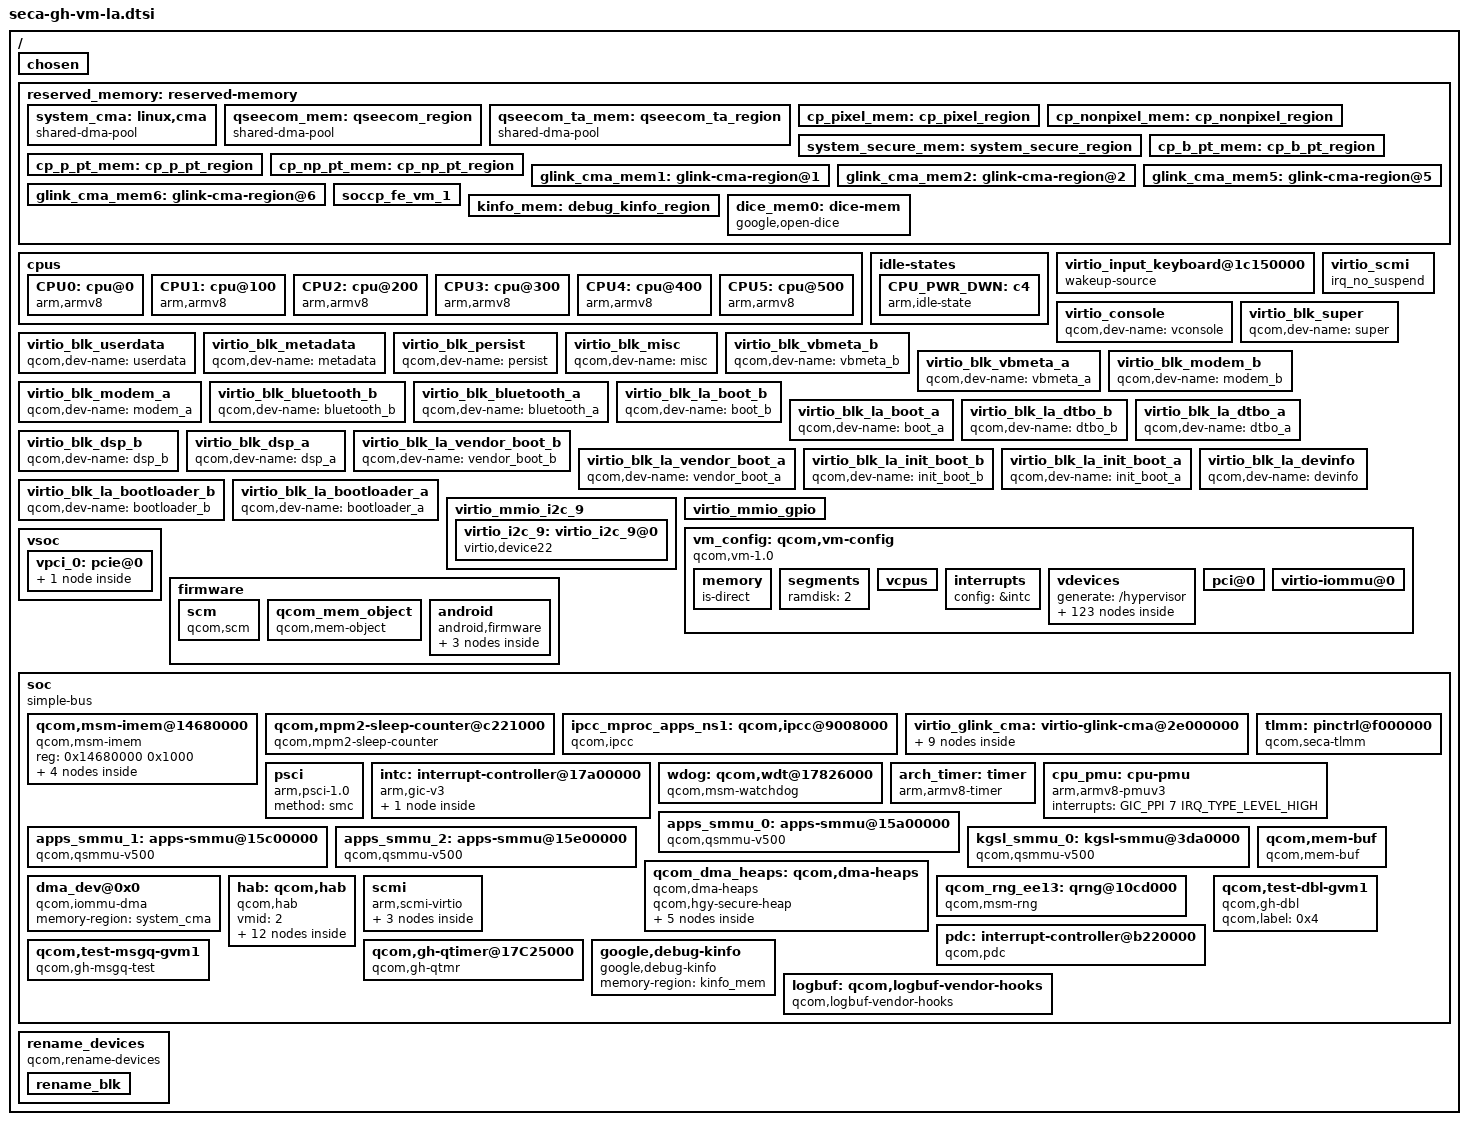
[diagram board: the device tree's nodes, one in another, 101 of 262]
// SPDX-License-Identifier: BSD-3-Clause
/*
 * Copyright (c) Qualcomm Technologies, Inc. and/or its subsidiaries.
 */

#include <dt-bindings/interrupt-controller/arm-gic.h>
#include <dt-bindings/arm/msm/qcom_dma_heap_dt_constants.h>
#include <dt-bindings/mailbox/qcom-ipcc.h>
#include <dt-bindings/soc/qcom,ipcc.h>
#include <dt-bindings/mailbox/qcom-ipcc-sa8797p.h>

/ {
	#address-cells = <0x2>;
	#size-cells = <0x2>;
	qcom,msm-name = "SA_GUNYAH_VM";
	interrupt-parent = <&intc>;

	chosen {
		bootargs = "console=hvc0 root=/dev/ram rw rootwait nokaslr log_buf_len=1M ufshcd-core.use_mcq_mode=n kpti=0 loglevel=8 printk.devkmsg=on maxcpus=6 driver_async_probe=arm-scmi fw_devlink.strict=1 iommu.strict=0";
		bootconfig = "androidboot.fstab_suffix=hgy.seca.qcom";
	};

	reserved_memory: reserved-memory {
		#address-cells = <2>;
		#size-cells = <2>;
		ranges;

		system_cma: linux,cma {
			compatible = "shared-dma-pool";
			alloc-ranges = <0x0 0x0 0x0 0xffffffff>;
			reusable;
			alignment = <0x0 0x400000>;
			size = <0x0 0x2000000>;
			linux,cma-default;
		};

		qseecom_mem: qseecom_region {
			compatible = "shared-dma-pool";
			alloc-ranges = <0x0 0x00000000 0x0 0xffffffff>;
			reusable;
			alignment = <0x0 0x400000>;
			size = <0x0 0x1400000>;
		};

		qseecom_ta_mem: qseecom_ta_region {
			compatible = "shared-dma-pool";
			alloc-ranges = <0x0 0x00000000 0x0 0xffffffff>;
			reusable;
			alignment = <0x0 0x400000>;
			size = <0x0 0x1000000>;
		};

		cp_pixel_mem: cp_pixel_region {
			no-map;
			qcom,target-vmid = <0xa>;
			qcom,label = <0xc0a>;
			qcom,unmapped;
		};

		cp_nonpixel_mem: cp_nonpixel_region {
			no-map;
			qcom,target-vmid = <0xb>;
			qcom,label = <0xc0b>;
			qcom,unmapped;
		};

		system_secure_mem: system_secure_region {
			no-map;
			qcom,label = <0xc09>;
			qcom,target-vmid = <0x9>;
			qcom,unmapped;
		};

		cp_b_pt_mem: cp_b_pt_region {
			qcom,label = <0x9A>;
			qcom,secure-pt-reserved;
		};

		cp_p_pt_mem: cp_p_pt_region {
			qcom,label = <0x9B>;
			qcom,secure-pt-reserved;
		};

		cp_np_pt_mem: cp_np_pt_region {
			qcom,label = <0x9C>;
			qcom,secure-pt-reserved;
		};

		glink_cma_mem1: glink-cma-region@1 {
			no-map;
			qcom,label = <0x60>;
		};

		glink_cma_mem2: glink-cma-region@2 {
			no-map;
			qcom,label = <0x61>;
		};

		glink_cma_mem5: glink-cma-region@5 {
			no-map;
			qcom,label = <0x64>;
		};

		glink_cma_mem6: glink-cma-region@6 {
			no-map;
			qcom,label = <0x65>;
		};

		soccp_fe_vm_1: soccp_fe_vm_1 {
			no-map;
			qcom,label = <0x80>;
		};

		kinfo_mem: debug_kinfo_region {
			alloc-ranges = <0x0 0x0 0xffffffff 0xffffffff>;
			size = <0x0 0x1000>;
			no-map;
		};

		dice_mem0: dice-mem {
			compatible = "google,open-dice";
			no-map;
			qcom,label = <0x67>;
		};

	};

	cpus {
		#address-cells = <0x2>;
		#size-cells = <0x0>;

		CPU0: cpu@0 {
			compatible = "arm,armv8";
			reg = <0x0 0x0>;
			device_type = "cpu";
			enable-method = "psci";
			cpu-idle-states = <&CPU_PWR_DWN>;
		};

		CPU1: cpu@100 {
			compatible = "arm,armv8";
			reg = <0x0 0x100>;
			device_type = "cpu";
			enable-method = "psci";
			cpu-idle-states = <&CPU_PWR_DWN>;
		};

		CPU2: cpu@200 {
			compatible = "arm,armv8";
			reg = <0x0 0x200>;
			device_type = "cpu";
			enable-method = "psci";
			cpu-idle-states = <&CPU_PWR_DWN>;
		};

		CPU3: cpu@300 {
			compatible = "arm,armv8";
			reg = <0x0 0x300>;
			device_type = "cpu";
			enable-method = "psci";
			cpu-idle-states = <&CPU_PWR_DWN>;
		};

		CPU4: cpu@400 {
			compatible = "arm,armv8";
			reg = <0x0 0x400>;
			device_type = "cpu";
			enable-method = "psci";
			cpu-idle-states = <&CPU_PWR_DWN>;
		};

		CPU5: cpu@500 {
			compatible = "arm,armv8";
			reg = <0x0 0x500>;
			device_type = "cpu";
			enable-method = "psci";
			cpu-idle-states = <&CPU_PWR_DWN>;
		};
	};

	idle-states {
		CPU_PWR_DWN: c4 { /* C4 */
			compatible = "arm,idle-state";
			idle-state-name = "ret";
			entry-latency-us = <93>;
			exit-latency-us = <129>;
			min-residency-us = <560>;
			arm,psci-suspend-param = <0x00000003>;
			local-timer-stop;
		};
	};

	virtio_input_keyboard@1c150000 {
		wakeup-source;
	};

	virtio_console {
		qcom,dev-name = "vconsole";
	};

	virtio_scmi {
		irq_no_suspend;
	};

	virtio_blk_super {
		qcom,dev-name = "super";
	};

	virtio_blk_userdata {
		qcom,dev-name = "userdata";
	};

	virtio_blk_metadata {
		qcom,dev-name = "metadata";
	};

	virtio_blk_persist {
		qcom,dev-name = "persist";
	};

	virtio_blk_misc {
		qcom,dev-name = "misc";
	};

	virtio_blk_vbmeta_b {
		qcom,dev-name = "vbmeta_b";
	};

	virtio_blk_vbmeta_a {
		qcom,dev-name = "vbmeta_a";
	};

	virtio_blk_modem_b {
		qcom,dev-name = "modem_b";
	};

	virtio_blk_modem_a {
		qcom,dev-name = "modem_a";
	};

	virtio_blk_bluetooth_b {
		qcom,dev-name = "bluetooth_b";
	};

	virtio_blk_bluetooth_a {
		qcom,dev-name = "bluetooth_a";
	};

	virtio_blk_la_boot_b {
		qcom,dev-name = "boot_b";
	};

	virtio_blk_la_boot_a {
		qcom,dev-name = "boot_a";
	};

	virtio_blk_la_dtbo_b {
		qcom,dev-name = "dtbo_b";
	};

	virtio_blk_la_dtbo_a {
		qcom,dev-name = "dtbo_a";
	};

	virtio_blk_dsp_b {
		qcom,dev-name = "dsp_b";
	};

	virtio_blk_dsp_a {
		qcom,dev-name = "dsp_a";
	};

	virtio_blk_la_vendor_boot_b {
		qcom,dev-name = "vendor_boot_b";
	};

	virtio_blk_la_vendor_boot_a {
		qcom,dev-name = "vendor_boot_a";
	};

	virtio_blk_la_init_boot_b {
		qcom,dev-name = "init_boot_b";
	};

	virtio_blk_la_init_boot_a {
		qcom,dev-name = "init_boot_a";
	};

	virtio_blk_la_devinfo {
		qcom,dev-name = "devinfo";
	};

	virtio_blk_la_bootloader_b {
		qcom,dev-name = "bootloader_b";
	};

	virtio_blk_la_bootloader_a {
		qcom,dev-name = "bootloader_a";
	};

	virtio_mmio_i2c_9 {
		virtio_i2c_9: virtio_i2c_9@0 {
			compatible = "virtio,device22";
		};
	};

	virtio_mmio_gpio {
	};

	vm_config: qcom,vm-config {
		compatible = "qcom,vm-1.0";
		vm-type = "aarch64-guest";
		boot-config = "fdt,unified";
		os-type = "linux";
		kernel-entry-segment = "kernel";
		kernel-entry-offset = <0x0 0x0>;
		vendor = "QTI";
		image-name = "qcom,autogvm";
		qcom,pasid = <0x0 0x2c>;
		qcom,qtee-config-info = "p=3,16,57,77,78,7A,7C,8F,97,159,199,47E,7F1,10C;ta=keymaster64,widevine,pr_3_0,she_gvm,wvqcomkeyprov,drmsampleapp,smpcpyap64,featenabler,auto_test_a,auto_test_b,auto_test_c,auto_test_d,auto_test_e,auto_test_f,auto_test_g,auto_test_h,auto_test_i,auto_test_j,auto_test_k,auto_test_l,auto_test_m,auto_test_n,auto_test_o,auto_test_p,auto_test_320,auto_test_321,auto_test_322,auto_test_323,auto_test_324,apttestapp,apttestapp64,aptcryptotestapp,aptcryptotestapp64,smplserv,tzecotestapp,tzecotestappcbo1,smci_auto_test_1,smci_auto_test_2,smci_auto_test_3,smci_auto_test_4,smci_auto_test_5,smci_auto_test_6,smci_auto_test_7,smci_auto_test_8,smci_auto_test_9,smci_auto_test_10,smci_auto_test_11,smci_auto_test_12,smci_auto_test_13,smci_auto_test_14,smci_auto_test_15,smci_auto_test_16,smci_auto_test_init_crash,smci_auto_test_restartable,smci_auto_test_shutdown_crash,fsp_test_1,fsp_test_2,fsp_test_3,bintestapp64,tzecotestapp1,crypto_testapp,sst_testapp,autosst_testapp,auto_test_unpermitted,FD02C9DA-306C-48C7-A49C-BBD827AE86EF,5AF8C3E6-D9DF-446E-4FF2-D4D58E8CA49B,19CE19B9-FD73-4262-8553-E5CAC40C895A,C02CAC07-2639-4EF0-BC12-C4AF1FB3E276,15C6B6E4-D083-48E4-8744-4D90A8FF1EF2,CAD10542-34E4-452D-6156-E979AA6E61BC,23914957-C174-4EA6-54D1-DA820F77B4B0,5AF8C3E6-D9DF-446E-4FF2-C3C47D7B938A,CAD10542-34E4-452D-6156-E979AA6E6132,5AF8C3E6-D9DF-446E-4FF2-B2B36C6A8279,5AF8C3E6-D9DF-446E-4FF2-D4D58E8CA49B,19CE19B9-FD73-4262-8553-E5CAC40C895A,C02CAC07-2639-4EF0-BC12-C4AF1FB3E276,15C6B6E4-D083-48E4-8744-4D90A8FF1EF2,CAD10542-34E4-452D-6156-E979AA6E61BC,23914957-C174-4EA6-54D1-DA820F77B4B0,5AF8C3E6-D9DF-446E-4FF2-C3C47D7B938A,CAD10542-34E4-452D-6156-E979AA6E6132,5AF8C3E6-D9DF-446E-4FF2-B2B36C6A8279,9824F733-FAC7-502A-81A0-84F6EE3DDACE,20F800CD-0E9B-55CF-A363-1498C26C7100,F577386D-AE4A-5728-921F-F97407BB30A0,3F3E0440-3CD7-5A81-A5DF-6AEB9A0A096C,2DB53398-CA4E-5342-BDED-4544A9039DEA,4C179CF2-22E0-5860-982F-5BBE195F9B0A,CE79BE1D-B0A5-5E69-87C6-6524649F1BEC,F54046B4-11FA-5F76-B4CC-39F58AF4011F,D1DB4C3F-B1E5-5A7F-817E-B49AF2632D1A,2F9D7B61-C79B-5D0B-8FA5-ECCFAE233B7C,220249E5-787C-5F61-B7E6-F69E589F37D6,D4ADCDC0-FF3F-52FA-9267-23971A192A73,0E0F184C-A5F3-543F-9CBF-5104168FE101,1B196214-0457-5774-B768-E8B6F139BECC,AE80F099-54A0-532B-A7BF-58DDB08F2407,E0C6693B-0945-5E72-9385-D71353B81721,10D761D9-037A-51E3-9955-028AF5A77FBA,D9BCD049-9321-52CC-B310-A62789FF3833,3BAA90A5-E4BA-52E9-9A63-EF71FF188B81,71BACACB-52EB-53A5-AA61-510923212679,8A0B3DF4-4947-49E4-85A7-67D7D73B5314,DC0ED4E6-819A-4560-BF13-B4948A7B4379,FF722055-FDC3-4C17-B53D-669E19A358F8,BEE83CCC-0DCC-420F-BAF6-F3F8B48DB22D,534D4152-542D-4353-4C54-2D54412D4552,534D4152-5443-534C-5445-5252544F4F53,534D4152-542D-4353-4C54-2D54412D5355,534D4152-5443-534C-544F-53345041524D,534D4152-542D-4353-4C54-2D54412D5354,534D4152-5443-534C-5443-4C4950415241,534D4152-5443-534C-5443-4C49504F5053,534D4152-542D-4353-4C54-2D54412D3031,534D4152-5443-534C-5441-544346494341,534d4152-5443-534c-5454-434649434132,534D4152-5443-534C-4D4C-54494E535443,534D4152-5443-534C-5347-4C494E535443,534D4152-5443-534C-434C-4F50414E4943,534D4152-5443-4C53-4152-4954484D4554,534D4152-5443-534C-5443-525950544F31,534D4152-5443-534C-5444-415441535431,534D4152-5443-534C-5F54-494D45415049,5AB106AE-7F60-11EA-BC55-0242AC130003,4E3F7FF3-7EDE-45FD-9BAA-7863611E0897,smplap64,ukpapp,unified_key_prov,ukpclnt,sbservice;";
		qcom,secdomain-ids = <52 9 10>;
		qcom,primary-vm-index = <0>;
		vm-attrs = "guest-ram-dump" ,"vpm-virq", "allow-unprotected";
		qcom,peripheral-vmids = <0x9 0xa 0xb>;

		virtio-iommu-stream-id-ranges-temp = <0x20000 0x10000 0x30000 0x10000>;
		vits-device-id-ranges-temp = <0xa0000 0x1 0xa0100 0x1 0xb0000 0x1 0xb0100 0x1>;

		memory {
			#address-cells = <0x2>;
			#size-cells = <0x0>;

			/* The IPA of the Guest regions is placed as IPA=PA */
			is-direct;
		};

		segments {
			ramdisk = <2>;
		};

		vcpus {
			config = "/cpus";
			affinity = "pinned";
			sched-priority = <0>;       /* relative to PVM */
			sched-timeslice = <5000>;   /* in ms */
		};

		interrupts {
			config = &intc;
		};

		vdevices {
			generate = "/hypervisor";

			minidump {
				vdevice-type = "minidump";
				push-compatible = "qcom,minidump_rm";
				minidump_allowed;
			};

			rm-rpc {
				vdevice-type = "rm-rpc";
				generate = "/hypervisor/qcom,resource-mgr";
				console-dev;
				message-size = <0x000000f0>;
				queue-depth = <0x00000008>;
				qcom,label = <0x1>;
			};

			virtio-mmio@0 {
				vdevice-type = "virtio-mmio";
				generate = "/virtio-mmio";
				peer-default;
				vqs-num = <0x1>;
				push-compatible = "virtio,mmio";
				sync-reset;
				dma-coherent;
				dma_base = <0x0 0x0>;
				memory {
					qcom,label = <0x20>;
					#address-cells = <0x2>;
					allocate-base;
				};
			};

			virtio-mmio@1 {
				vdevice-type = "virtio-mmio";
				patch = "/virtio_blk_la_devinfo";
				peer-default;
				vqs-num = <0x1>;
				push-compatible = "virtio,mmio";
				sync-reset;
				dma-coherent;
				dma_base = <0x0 0x4000>;
				memory {
					qcom,label = <0x21>;
					#address-cells = <0x2>;
					allocate-base;
				};
			};

			virtio-mmio@2 {
				vdevice-type = "virtio-mmio";
				patch = "/virtio_blk_la_init_boot_a";
				peer-default;
				vqs-num = <0x1>;
				push-compatible = "virtio,mmio";
				sync-reset;
				dma-coherent;
				dma_base = <0x0 0x8000>;
				memory {
					qcom,label = <0x22>;
					#address-cells = <0x2>;
					allocate-base;
				};
			};

			virtio-mmio@3 {
				vdevice-type = "virtio-mmio";
				patch = "/virtio_blk_la_init_boot_b";
				peer-default;
				vqs-num = <0x1>;
				push-compatible = "virtio,mmio";
				sync-reset;
				dma-coherent;
				dma_base = <0x0 0xC000>;
				memory {
					qcom,label = <0x23>;
					#address-cells = <0x2>;
					allocate-base;
				};
			};

			virtio-mmio@4 {
				vdevice-type = "virtio-mmio";
				patch = "/virtio_blk_la_vendor_boot_a";
				peer-default;
				vqs-num = <0x1>;
				push-compatible = "virtio,mmio";
				sync-reset;
				dma-coherent;
				dma_base = <0x0 0x10000>;
				memory {
					qcom,label = <0x24>;
					#address-cells = <0x2>;
					allocate-base;
				};
			};

			virtio-mmio@5 {
				vdevice-type = "virtio-mmio";
				patch = "/virtio_blk_la_vendor_boot_b";
				peer-default;
				vqs-num = <0x1>;
				push-compatible = "virtio,mmio";
				sync-reset;
				dma-coherent;
				dma_base = <0x0 0x14000>;
				memory {
					qcom,label = <0x25>;
					#address-cells = <0x2>;
					allocate-base;
				};
			};

			virtio-mmio@6 {
				vdevice-type = "virtio-mmio";
				patch = "/virtio_blk_dsp_a";
				peer-default;
				vqs-num = <0x1>;
				push-compatible = "virtio,mmio";
				sync-reset;
				dma-coherent;
				dma_base = <0x0 0x18000>;
				memory {
					qcom,label = <0x26>;
					#address-cells = <0x2>;
					allocate-base;
				};
			};

			virtio-mmio@7 {
				vdevice-type = "virtio-mmio";
				patch = "/virtio_blk_dsp_b";
				peer-default;
				vqs-num = <0x1>;
				push-compatible = "virtio,mmio";
				sync-reset;
				dma-coherent;
				dma_base = <0x0 0x1C000>;
				memory {
					qcom,label = <0x27>;
					#address-cells = <0x2>;
					allocate-base;
				};
			};

			virtio-mmio@8 {
				vdevice-type = "virtio-mmio";
				patch = "/virtio_blk_la_dtbo_a";
				peer-default;
				vqs-num = <0x1>;
				push-compatible = "virtio,mmio";
				sync-reset;
				dma-coherent;
				dma_base = <0x0 0x20000>;
				memory {
					qcom,label = <0x28>;
					#address-cells = <0x2>;
					allocate-base;
				};
			};

			virtio-mmio@9 {
				vdevice-type = "virtio-mmio";
				patch = "/virtio_blk_la_dtbo_b";
				peer-default;
				vqs-num = <0x1>;
				push-compatible = "virtio,mmio";
				sync-reset;
				dma-coherent;
				dma_base = <0x0 0x24000>;
				memory {
					qcom,label = <0x29>;
					#address-cells = <0x2>;
					allocate-base;
				};
			};

			virtio-mmio@10 {
				vdevice-type = "virtio-mmio";
				patch = "/virtio_blk_la_boot_a";
				peer-default;
				vqs-num = <0x1>;
				push-compatible = "virtio,mmio";
				sync-reset;
				dma-coherent;
				dma_base = <0x0 0x28000>;
				memory {
					qcom,label = <0x2A>;
					#address-cells = <0x2>;
					allocate-base;
				};
			};

			virtio-mmio@11 {
				vdevice-type = "virtio-mmio";
				patch = "/virtio_blk_la_boot_b";
				peer-default;
				vqs-num = <0x1>;
				push-compatible = "virtio,mmio";
				sync-reset;
				dma-coherent;
				dma_base = <0x0 0x2C000>;
				memory {
					qcom,label = <0x2B>;
					#address-cells = <0x2>;
					allocate-base;
				};
			};

			virtio-mmio@12 {
				vdevice-type = "virtio-mmio";
				patch = "/virtio_blk_bluetooth_a";
				peer-default;
				vqs-num = <0x1>;
				push-compatible = "virtio,mmio";
				sync-reset;
				dma-coherent;
				dma_base = <0x0 0x30000>;
				memory {
					qcom,label = <0x2C>;
					#address-cells = <0x2>;
					allocate-base;
				};
			};

			virtio-mmio@13 {
				vdevice-type = "virtio-mmio";
				patch = "/virtio_blk_bluetooth_b";
				peer-default;
				vqs-num = <0x1>;
				push-compatible = "virtio,mmio";
				sync-reset;
				dma-coherent;
				dma_base = <0x0 0x34000>;
				memory {
					qcom,label = <0x2D>;
					#address-cells = <0x2>;
					allocate-base;
				};
			};

			virtio-mmio@14 {
				vdevice-type = "virtio-mmio";
				patch = "/virtio_blk_modem_a";
				peer-default;
				vqs-num = <0x1>;
				push-compatible = "virtio,mmio";
				sync-reset;
				dma-coherent;
				dma_base = <0x0 0x38000>;
				memory {
					qcom,label = <0x2E>;
					#address-cells = <0x2>;
					allocate-base;
				};
			};

			virtio-mmio@15 {
				vdevice-type = "virtio-mmio";
				patch = "/virtio_blk_modem_b";
				peer-default;
				vqs-num = <0x1>;
				push-compatible = "virtio,mmio";
				sync-reset;
				dma-coherent;
				dma_base = <0x0 0x3C000>;
				memory {
					qcom,label = <0x2F>;
					#address-cells = <0x2>;
					allocate-base;
				};
			};

			virtio-mmio@16 {
				vdevice-type = "virtio-mmio";
				patch = "/virtio_blk_vbmeta_a";
				peer-default;
				vqs-num = <0x1>;
				push-compatible = "virtio,mmio";
				sync-reset;
				dma-coherent;
				dma_base = <0x0 0x40000>;
				memory {
					qcom,label = <0x30>;
					#address-cells = <0x2>;
					allocate-base;
				};
			};

			virtio-mmio@17 {
				vdevice-type = "virtio-mmio";
				patch = "/virtio_blk_vbmeta_b";
				peer-default;
				vqs-num = <0x1>;
				push-compatible = "virtio,mmio";
				sync-reset;
				dma-coherent;
				dma_base = <0x0 0x44000>;
				memory {
					qcom,label = <0x31>;
					#address-cells = <0x2>;
					allocate-base;
				};
			};

			virtio-mmio@18 {
				vdevice-type = "virtio-mmio";
				patch = "/virtio_blk_misc";
				peer-default;
				vqs-num = <0x1>;
				push-compatible = "virtio,mmio";
				sync-reset;
				dma-coherent;
				dma_base = <0x0 0x48000>;
				memory {
					qcom,label = <0x32>;
					#address-cells = <0x2>;
					allocate-base;
				};
			};

			virtio-mmio@19 {
				vdevice-type = "virtio-mmio";
				patch = "/virtio_blk_persist";
				peer-default;
				vqs-num = <0x1>;
				push-compatible = "virtio,mmio";
				sync-reset;
				dma-coherent;
				dma_base = <0x0 0x4C000>;
				memory {
					qcom,label = <0x33>;
					#address-cells = <0x2>;
					allocate-base;
				};
			};

			virtio-mmio@20 {
				vdevice-type = "virtio-mmio";
				patch = "/virtio_blk_metadata";
				peer-default;
				vqs-num = <0x1>;
				push-compatible = "virtio,mmio";
				sync-reset;
				dma-coherent;
				dma_base = <0x0 0x50000>;
				memory {
					qcom,label = <0x34>;
					#address-cells = <0x2>;
					allocate-base;
				};
			};

			virtio-mmio@21 {
				vdevice-type = "virtio-mmio";
				patch = "/virtio_blk_userdata";
				peer-default;
				vqs-num = <0x1>;
				push-compatible = "virtio,mmio";
				sync-reset;
				dma-coherent;
				dma_base = <0x0 0x54000>;
				memory {
					qcom,label = <0x35>;
					#address-cells = <0x2>;
					allocate-base;
				};
			};

			virtio-mmio@22 {
				vdevice-type = "virtio-mmio";
				patch = "/virtio_blk_super";
				peer-default;
				vqs-num = <0x1>;
				push-compatible = "virtio,mmio";
				sync-reset;
				dma-coherent;
				dma_base = <0x0 0x58000>;
				memory {
					qcom,label = <0x36>;
					#address-cells = <0x2>;
					allocate-base;
				};
			};

			/* Virtio net 0 device */
			virtio-mmio@23 {
				vdevice-type = "virtio-mmio";
				generate = "/virtio-mmio";
				peer-default;
				vqs-num = <0x2>;
				push-compatible = "virtio,mmio";
				sync-reset;
				dma-coherent;
				dma_base = <0x0 0x5C000>;
				memory {
					qcom,label = <0x37>;
					#address-cells = <0x2>;
					allocate-base;
				};
			};

			/* Virtio net 1 device */
			virtio-mmio@24 {
				vdevice-type = "virtio-mmio";
				generate = "/virtio-mmio";
				peer-default;
				vqs-num = <0x2>;
				push-compatible = "virtio,mmio";
				sync-reset;
				dma-coherent;
				dma_base = <0x0 0x64000>;
				memory {
					qcom,label = <0x38>;
					#address-cells = <0x2>;
					allocate-base;
				};
			};

			/* HAB 0 device */
			virtio-mmio@25 {
				vdevice-type = "virtio-mmio";
				generate = "/virtio-mmio";
				peer-default;
				vqs-num = <0x2>;
				push-compatible = "virtio,mmio";
				sync-reset;
				dma-coherent;
				dma_base = <0x0 0x6C000>;
				memory {
					qcom,label = <0x39>;
					#address-cells = <0x2>;
					allocate-base;
				};
			};

			/* HAB 1 device */
			virtio-mmio@26 {
				vdevice-type = "virtio-mmio";
				generate = "/virtio-mmio";
				peer-default;
				vqs-num = <0x2>;
				push-compatible = "virtio,mmio";
				sync-reset;
				dma-coherent;
				dma_base = <0x0 0x7C000>;
				memory {
					qcom,label = <0x3A>;
					#address-cells = <0x2>;
					allocate-base;
				};
			};

			/* HAB 2 device */
			virtio-mmio@27 {
				vdevice-type = "virtio-mmio";
				generate = "/virtio-mmio";
				peer-default;
				vqs-num = <0x8>;
				push-compatible = "virtio,mmio";
				sync-reset;
				dma-coherent;
				dma_base = <0x0 0x8C000>;
				memory {
					qcom,label = <0x3B>;
					#address-cells = <0x2>;
					allocate-base;
				};
			};

			/* HAB 3 device */
			virtio-mmio@28 {
				vdevice-type = "virtio-mmio";
				generate = "/virtio-mmio";
				peer-default;
				vqs-num = <0xA>;
				push-compatible = "virtio,mmio";
				sync-reset;
				dma-coherent;
				dma_base = <0x0 0xCC000>;
				memory {
					qcom,label = <0x3C>;
					#address-cells = <0x2>;
					allocate-base;
				};
			};

			/* HAB 4 device */
			virtio-mmio@29 {
				vdevice-type = "virtio-mmio";
				generate = "/virtio-mmio";
				peer-default;
				vqs-num = <0x6>;
				push-compatible = "virtio,mmio";
				sync-reset;
				dma-coherent;
				dma_base = <0x0 0x11C000>;
				memory {
					qcom,label = <0x3D>;
					#address-cells = <0x2>;
					allocate-base;
				};
			};

			/* HAB 5 device */
			virtio-mmio@30 {
				vdevice-type = "virtio-mmio";
				generate = "/virtio-mmio";
				peer-default;
				vqs-num = <0x6>;
				push-compatible = "virtio,mmio";
				sync-reset;
				dma-coherent;
				dma_base = <0x0 0x14C000>;
				memory {
					qcom,label = <0x3E>;
					#address-cells = <0x2>;
					allocate-base;
				};
			};

			/* Virtio input 0 device */
			virtio-mmio@31 {
				vdevice-type = "virtio-mmio";
				generate = "/virtio-mmio";
				virtio,device-type = <18>;
				peer-default;
				vqs-num = <0x2>;
				push-compatible = "virtio,mmio";
				sync-reset;
				dma-coherent;
				dma_base = <0x0 0x17C000>;
				memory {
					qcom,label = <0x3F>;
					#address-cells = <0x2>;
					allocate-base;
				};
			};

			/* Virtio input 1 device */
			virtio-mmio@32 {
				vdevice-type = "virtio-mmio";
				patch = "/virtio_input_keyboard@1c150000";
				virtio,device-type = <18>;
				peer-default;
				vqs-num = <0x2>;
				push-compatible = "virtio,mmio";
				sync-reset;
				dma-coherent;
				dma_base = <0x0 0x180000>;
				memory {
					qcom,label = <0x40>;
					#address-cells = <0x2>;
					allocate-base;
				};
			};

			/* Virtio console device */
			virtio-mmio@33 {
				vdevice-type = "virtio-mmio";
				patch = "/virtio_console";
				peer-default;
				vqs-num = <0x2>;
				push-compatible = "virtio,mmio";
				sync-reset;
				dma-coherent;
				dma_base = <0x0 0x184000>;
				memory {
					qcom,label = <0x41>;
					#address-cells = <0x2>;
					allocate-base;
				};
			};

			/* Virtio SCMI device */
			virtio-mmio@34 {
				vdevice-type = "virtio-mmio";
				patch = "/virtio_scmi";
				peer-default;
				vqs-num = <0x2>;
				push-compatible = "virtio,mmio";
				sync-reset;
				dma-coherent;
				dma_base = <0x0 0x18C000>;
				memory {
					qcom,label = <0x42>;
					#address-cells = <0x2>;
					allocate-base;
				};
			};

			/* Virtio vsock device */
			virtio-mmio@35 {
				vdevice-type = "virtio-mmio";
				generate = "/virtio-mmio";
				peer-default;
				vqs-num = <0x3>;
				push-compatible = "virtio,mmio";
				sync-reset;
				dma-coherent;
				dma_base = <0x0 0x194000>;
				memory {
					qcom,label = <0x43>;
					#address-cells = <0x2>;
					allocate-base;
				};
			};

			/* Virtio glink device */
			virtio-mmio@36 {
				vdevice-type = "virtio-mmio";
				patch = "/soc/virtio-glink-cma@2e000000";
				peer-default;
				vqs-num = <0x1>;
				push-compatible = "virtio,mmio";
				sync-reset;
				dma-coherent;
				dma_base = <0x0 0x1A0000>;
				memory {
					qcom,label = <0x44>;
					#address-cells = <0x2>;
					allocate-base;
				};
			};

			/* Virtio FastRPC device */
			virtio-mmio@37 {
				vdevice-type = "virtio-mmio";
				generate = "/virtio-mmio";
				peer-default;
				vqs-num = <0x2>;
				push-compatible = "virtio,mmio";
				sync-reset;
				dma-coherent;
				dma_base = <0x0 0x1A2000>;
				memory {
					qcom,label = <0x45>;
					#address-cells = <0x2>;
					allocate-base;
				};
			};

			/* Virtio I2C device */
			virtio-mmio@38 {
				vdevice-type = "virtio-mmio";
				generate = "/virtio-mmio";
				peer-default;
				vqs-num = <0x1>;
				push-compatible = "virtio,mmio";
				sync-reset;
				dma-coherent;
				dma_base = <0x0 0x1A6000>;
				memory {
					qcom,label = <0x46>;
					#address-cells = <0x2>;
					allocate-base;
				};
			};

			/* Virtio SSR device */
			virtio-mmio@39 {
				vdevice-type = "virtio-mmio";
				generate = "/virtio-mmio";
				peer-default;
				vqs-num = <0x1>;
				push-compatible = "virtio,mmio";
				sync-reset;
				dma-coherent;
				dma_base = <0x0 0x1A8000>;
				memory {
					qcom,label = <0x47>;
					#address-cells = <0x2>;
					allocate-base;
				};
			};

			/* VHAB 6 device */
			virtio-mmio@40 {
				vdevice-type = "virtio-mmio";
				generate = "/virtio-mmio";
				peer-default;
				vqs-num = <0x2>;
				push-compatible = "virtio,mmio";
				sync-reset;
				dma-coherent;
				dma_base = <0x0 0x1AA000>;
				memory {
					qcom,label = <0x48>;
					#address-cells = <0x2>;
					allocate-base;
				};
			};

			/* VHAB 7 device */
			virtio-mmio@41 {
				vdevice-type = "virtio-mmio";
				generate = "/virtio-mmio";
				peer-default;
				vqs-num = <0x2>;
				push-compatible = "virtio,mmio";
				sync-reset;
				dma-coherent;
				dma_base = <0x0 0x1BA000>;
				memory {
					qcom,label = <0x49>;
					#address-cells = <0x2>;
					allocate-base;
				};
			};

			/* VHAB 8 device */
			virtio-mmio@42 {
				vdevice-type = "virtio-mmio";
				generate = "/virtio-mmio";
				peer-default;
				vqs-num = <0x6>;
				push-compatible = "virtio,mmio";
				sync-reset;
				dma-coherent;
				dma_base = <0x0 0x1CA000>;
				memory {
					qcom,label = <0x4A>;
					#address-cells = <0x2>;
					allocate-base;
				};
			};

			/* VHAB 9 device */
			virtio-mmio@43 {
				vdevice-type = "virtio-mmio";
				generate = "/virtio-mmio";
				peer-default;
				vqs-num = <0x2>;
				push-compatible = "virtio,mmio";
				sync-reset;
				dma-coherent;
				dma_base = <0x0 0x1FA000>;
				memory {
					qcom,label = <0x4B>;
					#address-cells = <0x2>;
					allocate-base;
				};
			};

			/* VHAB 10 device */
			virtio-mmio@44 {
				vdevice-type = "virtio-mmio";
				generate = "/virtio-mmio";
				peer-default;
				vqs-num = <0x4>;
				push-compatible = "virtio,mmio";
				sync-reset;
				dma-coherent;
				dma_base = <0x0 0x22A000>;
				memory {
					qcom,label = <0x4C>;
					#address-cells = <0x2>;
					allocate-base;
				};
			};

			/* VHAB 11 device */
			virtio-mmio@45 {
				vdevice-type = "virtio-mmio";
				generate = "/virtio-mmio";
				peer-default;
				vqs-num = <0x2>;
				push-compatible = "virtio,mmio";
				sync-reset;
				dma-coherent;
				dma_base = <0x0 0x25A000>;
				memory {
					qcom,label = <0x4D>;
					#address-cells = <0x2>;
					allocate-base;
				};
			};

			/* VBLK la_bootloader_a device */
			virtio-mmio@46 {
				vdevice-type = "virtio-mmio";
				patch = "/virtio_blk_la_bootloader_a";
				peer-default;
				vqs-num = <0x1>;
				push-compatible = "virtio,mmio";
				sync-reset;
				dma-coherent;
				dma_base = <0x0 0x28A000>;
				memory {
					qcom,label = <0x4E>;
					#address-cells = <0x2>;
					allocate-base;
				};
			};

			/* VBLK la_bootloader_b device */
			virtio-mmio@47 {
				vdevice-type = "virtio-mmio";
				patch = "/virtio_blk_la_bootloader_b";
				peer-default;
				vqs-num = <0x1>;
				push-compatible = "virtio,mmio";
				sync-reset;
				dma-coherent;
				dma_base = <0x0 0x28E000>;
				memory {
					qcom,label = <0x4F>;
					#address-cells = <0x2>;
					allocate-base;
				};
			};


			/* Virtio I2C device for USB-Linked Peripherals */
			virtio-mmio@48 {
				vdevice-type = "virtio-mmio";
				patch = "/virtio_mmio_i2c_9";
				peer-default;
				vqs-num = <0x1>;
				push-compatible = "virtio,mmio";
				sync-reset;
				dma-coherent;
				dma_base = <0x0 0x292000>;
				memory {
					qcom,label = <0x51>;
					#address-cells = <0x2>;
					allocate-base;
				};
			};

			/* virtio eavb */
			virtio-mmio@49 {
				vdevice-type = "virtio-mmio";
				generate = "/virtio-mmio";
				peer-default;
				vqs-num = <0x2>;
				push-compatible = "virtio,mmio";
				sync-reset;
				dma-coherent;
				dma_base = <0x0 0x294000>;
				memory {
					qcom,label = <0x52>;
					#address-cells = <0x2>;
					allocate-base;
				};
			};

			/* GPIO virtio */
			virtio-mmio@50 {
				vdevice-type = "virtio-mmio";
				patch = "/virtio_mmio_gpio";
				peer-default;
				vqs-num = <0x2>;
				push-compatible = "virtio,mmio";
				sync-reset;
				dma-coherent;
				dma_base = <0x0 0x2D4000>;
				memory {
					qcom,label = <0x53>;
					#address-cells = <0x2>;
					allocate-base;
				};
			};


			/* Reserved device */
			virtio-mmio@51 {
				vdevice-type = "virtio-mmio";
				generate = "/virtio-mmio";
				peer-default;
				vqs-num = <0x2>;
				push-compatible = "virtio,mmio";
				sync-reset;
				dma-coherent;
				dma_base = <0x0 0x2D8000>;
				memory {
					qcom,label = <0x54>;
					#address-cells = <0x2>;
					allocate-base;
				};
			};

			vsmmu@15a00000 {
				vdevice-type = "vsmmu-v2";
				smmu-handle = <0x15a00000>;
				num-cbs = <0x8>;
				num-smrs = <0x8>;
				patch = "/soc/apps-smmu@15a00000";
			};

			vsmmu@15c00000 {
				vdevice-type = "vsmmu-v2";
				smmu-handle = <0x15c00000>;
				num-cbs = <0xb>;
				num-smrs = <0xb>;
				patch = "/soc/apps-smmu@15c00000";
			};

			vsmmu@15e00000 {
				vdevice-type = "vsmmu-v2";
				smmu-handle = <0x15e00000>;
				num-cbs = <0x1>;
				num-smrs = <0xc>;
				patch = "/soc/apps-smmu@15e00000";
			};

			vsmmu@3da0000 {
				vdevice-type = "vsmmu-v2";
				smmu-handle = <0x3da0000>;
				num-cbs = <0x1>;
				num-smrs = <0x1>;
				patch = "/soc/kgsl-smmu@3da0000";
			};

			swiotlb-shm {
				vdevice-type = "shm";
				generate = "/swiotlb";
				push-compatible = "swiotlb";
				peer-default;
				dma_base = <0x0 0x200000>;
				memory {
					qcom,label = <0x50>;
					#address-cells = <0x2>;
					allocate-base;
				};
			};

			hab_virq_dbl5 {
				vdevice-type = "doorbell";
				generate = "/hypervisor/hab_virq_5";
				qcom,label = <0x5>;
				push-compatible = "qcom,msm-virt_irq";
				peer-default;
			};

			hab_virq_dbl6 {
				vdevice-type = "doorbell";
				generate = "/hypervisor/hab_virq_6";
				qcom,label = <0x6>;
				push-compatible = "qcom,msm-virt_irq";
				peer-default;
			};

			hab_virq_dbl9 {
				vdevice-type = "doorbell";
				generate = "/hypervisor/hab_virq_9";
				qcom,label = <0x9>;
				push-compatible = "qcom,msm-virt_irq";
				peer-default;
			};

			hab_virq_dbl10 {
				vdevice-type = "doorbell";
				generate = "/hypervisor/hab_virq_a";
				qcom,label = <0xa>;
				push-compatible = "qcom,msm-virt_irq";
				peer-default;
			};

			hab_virq_dbl11 {
				vdevice-type = "doorbell";
				generate = "/hypervisor/hab_virq_b";
				qcom,label = <0xb>;
				push-compatible = "qcom,msm-virt_irq";
				peer-default;
			};

			hab_virq_dbl12 {
				vdevice-type = "doorbell";
				generate = "/hypervisor/hab_virq_c";
				qcom,label = <0xc>;
				push-compatible = "qcom,msm-virt_irq";
				peer-default;
			};

			vrtc {
				vdevice-type = "vrtc-pl031";
				peer-default;
				allocate-base;
			};

			test-dbl-gvm1 {
				vdevice-type = "doorbell";
				generate = "/hypervisor/test-dbl-gvm1";
				qcom,label = <0x4>;
				peer-default;
			};

			test-dbl-gvm1-source {
				vdevice-type = "doorbell-source";
				generate = "/hypervisor/test-dbl-gvm1-source";
				qcom,label = <0x4>;
				peer-default;
			};

			test-msgq-gvm1 {
				vdevice-type = "message-queue-pair";
				generate = "/hypervisor/test-msgq-gvm1-pair";
				message-size = <0xf0>;
				queue-depth = <0x8>;
				qcom,label = <0x4>;
				peer-default;
			};

			vcpu-sched-test-msgq {
				vdevice-type = "message-queue-pair";
				generate = "/hypervisor/sched-test-msgq-pair";
				message-size = <0xf0>;
				queue-depth = <0x8>;
				qcom,label = <0x8>;
				peer-default;
			};

		};

		pci@0 {
			vdevice-type = "pci";
			patch = "/vsoc/pcie@0";
			config-base-address = <0x0 0x28200000>;
			config-size = <0x0 0x200000>;
			npmem-base-address = <0x0 0x28100000>;
			npmem-size = <0x0 0x100000>;
			enable-msi;
			dma-coherent;
		};

		virtio-iommu@0 {
			vdevice-type = "virtio-iommu";
			/*
			 * Use existing PCI config below, no patch or generate
			 * The HW address of the target SMMUv3
			 */
			smmu-handle = <0x0 0x9980000>;
			/*
			 * How many stream do we expect to support on this interface
			 * to limit memory consumption
			 */
			max-streams = <10>;
			pci-slot-index = <0x1>;
		};
	};

	vsoc: vsoc {
		/*
		 * Virtual PCI device for Virtio-iommu
		 * RM is now choosing the addr for this bus, use the index instead
		 */
		vpci_0: pcie@0 {
			/* Device @1,0 matches up with pci-slot-index <0x1> vm-config */
			virtio_iommu0: virtio-iommu@1,0 {
				/* This IOMMU programming interface uses slot 00:01.0 */
				compatible = "pci1af4,1057";
				reg = <0x00000800 0x0 0x0 0x0 0x0>;
				#iommu-cells = <1>;
			};
		};
	};

	firmware: firmware {
		scm {
			compatible = "qcom,scm";
		};

		qcom_mem_object {
			compatible = "qcom,mem-object";
		};

		android {
			compatible = "android,firmware";
			boot_devices = "28031000.virtio_blk_la_bootloader_b,28030000.virtio_blk_la_bootloader_a,28003000.virtio_blk_la_devinfo,28004000.virtio_blk_la_init_boot_a,28005000.virtio_blk_la_init_boot_b,28006000.virtio_blk_la_vendor_boot_a,28007000.virtio_blk_la_vendor_boot_b,28008000.virtio_blk_dsp_a,28009000.virtio_blk_dsp_b,2800a000.virtio_blk_la_dtbo_a,2800b000.virtio_blk_la_dtbo_b,2800c000.virtio_blk_la_boot_a,2800d000.virtio_blk_la_boot_b,2800e000.virtio_blk_bluetooth_a,2800f000.virtio_blk_bluetooth_b,28010000.virtio_blk_modem_a,28011000.virtio_blk_modem_b,28012000.virtio_blk_vbmeta_a,28013000.virtio_blk_vbmeta_b,28014000.virtio_blk_misc,28015000.virtio_blk_persist,28016000.virtio_blk_metadata,28017000.virtio_blk_userdata,28018000.virtio_blk_super";

			vbmeta {
				compatible = "android,vbmeta";
				parts = "vbmeta,system,vendor";
			};

			fstab {
				compatible = "android,fstab";
				vendor {
					compatible = "android,vendor";
					dev="/dev/block/platform/vdevs/1c0f0000.virtio_blk/vdc";
					type = "ext4";
					mnt_flags = "ro,barrier=1,discard";
					fsmgr_flags = "wait";
					status = "disabled";
				};
			};
		};
	};

	soc: soc { };
};

&soc {
	#address-cells = <1>;
	#size-cells = <1>;
	ranges = <0 0 0 0xffffffff>;
	compatible = "simple-bus";

	qcom,msm-imem@14680000 {
		compatible = "qcom,msm-imem";
		reg = <0x14680000 0x1000>;
		ranges = <0x0 0x14680000 0x1000>;
		#address-cells = <1>;
		#size-cells = <1>;
		status = "ok";
		boot_stats@6b0 {
			compatible = "qcom,msm-imem-boot_stats";
			reg = <0x6b0 0x20>;
		};

		mem_dump_table@10 {
			compatible = "qcom,msm-imem-mem_dump_table";
			reg = <0x10 0x8>;
		};

		dload_type@1c {
			compatible = "qcom,msm-imem-dload-type";
			reg = <0x1c 0x4>;
		};

		diag_dload@c8 {
			compatible = "qcom,msm-imem-diag-dload";
			reg = <0xc8 0xc8>;
		};
	};

	qcom,mpm2-sleep-counter@c221000 {
			compatible = "qcom,mpm2-sleep-counter";
			reg = <0xc221000 0x1000>;
			clock-frequency = <32768>;
	};

	ipcc_mproc_apps_ns1: qcom,ipcc@9008000 {
		compatible = "qcom,ipcc";
		reg = <0x9008000 0x1000>;
		interrupts = <GIC_SPI 439 IRQ_TYPE_LEVEL_HIGH>;
		interrupt-controller;
		#interrupt-cells = <3>;
		#mbox-cells = <2>;
		status = "ok";
	};

	virtio_glink_cma: virtio-glink-cma@2e000000 {
		glink_bridge: virtio-glink-bridge {
			compatible = "virtio,device49162";
			remoteproc_cdsp_glink: glink-edge {
				interrupt-parent = <&ipcc_mproc_apps_ns1>;
				interrupts = <IPCC_MPROC_NSP0 0 IRQ_TYPE_EDGE_RISING>;
				mboxes = <&ipcc_mproc_apps_ns1 IPCC_MPROC_NSP0 0>;
				label = "cdsp";
				qcom,glink-label = "cdsp";
			};

			remoteproc_cdsp1_glink: glink-edge1 {
				interrupt-parent = <&ipcc_mproc_apps_ns1>;
				interrupts = <IPCC_MPROC_NSP1 0 IRQ_TYPE_EDGE_RISING>;
				mboxes = <&ipcc_mproc_apps_ns1 IPCC_MPROC_NSP1 0>;
				label = "cdsp1";
				qcom,glink-label = "cdsp1";
			};

			remoteproc_hpass0_glink: glink-edge4 {
				interrupt-parent = <&ipcc_mproc_apps_ns1>;
				interrupts = <IPCC_MPROC_ADSP0 0 IRQ_TYPE_EDGE_RISING>;
				mboxes = <&ipcc_mproc_apps_ns1 IPCC_MPROC_ADSP0 0>;
				label = "adsp";
				qcom,glink-label = "adsp";
			};

			remoteproc_hpass1_glink: glink-edge5 {
				interrupt-parent = <&ipcc_mproc_apps_ns1>;
				interrupts = <IPCC_MPROC_ADSP1 0 IRQ_TYPE_EDGE_RISING>;
				mboxes = <&ipcc_mproc_apps_ns1 IPCC_MPROC_ADSP1 0>;
				label = "adsp1";
				qcom,glink-label = "adsp1";
			};
		};
	};

	tlmm: pinctrl@f000000 {
		compatible = "qcom,seca-tlmm";
		reg = <0xf000000 0x1000000>;
		interrupts = <GIC_SPI 208 IRQ_TYPE_LEVEL_HIGH>;
		gpio-controller;
		#gpio-cells = <2>;
		interrupt-controller;
		#interrupt-cells = <2>;
	};

	psci {
		compatible = "arm,psci-1.0";
		method = "smc";
	};

	intc: interrupt-controller@17a00000 {
		compatible = "arm,gic-v3";
		interrupt-controller;
		#interrupt-cells = <0x3>;
		#redistributor-regions = <1>;
		redistributor-stride = <0x0 0x20000>;
		reg = <0x17a00000 0x10000>, /* GICD */
		      <0x17a60000 0x240000>; /* GICR * 18 */
		interrupts = <GIC_PPI 9 IRQ_TYPE_LEVEL_HIGH>;
		gic_its: msi-controller@0x17040000 {
			compatible = "arm,gic-v3-its";
			msi-controller;
			#msi-cells = <1>;
			reg = <0x17040000 0x20000>;
		};
	};

	wdog: qcom,wdt@17826000 {
		compatible = "qcom,msm-watchdog";
		reg = <0x17826000 0x1000>;
		reg-names = "wdt-base";
		interrupts = <GIC_SPI 0 IRQ_TYPE_LEVEL_HIGH>,
			<GIC_SPI 1 IRQ_TYPE_LEVEL_HIGH>;
		qcom,bark-time = <11000>;
		qcom,pet-time = <9360>;
		qcom,ipi-ping;
		qcom,wakeup-enable;
	};

	arch_timer: timer {
		compatible = "arm,armv8-timer";
		always-on;
		interrupts = <GIC_PPI 13 (GIC_CPU_MASK_SIMPLE(8) | IRQ_TYPE_LEVEL_LOW)>,
			     <GIC_PPI 14 (GIC_CPU_MASK_SIMPLE(8) | IRQ_TYPE_LEVEL_LOW)>,
			     <GIC_PPI 11 (GIC_CPU_MASK_SIMPLE(8) | IRQ_TYPE_LEVEL_LOW)>,
			     <GIC_PPI 12 (GIC_CPU_MASK_SIMPLE(8) | IRQ_TYPE_LEVEL_LOW)>;
		clock-frequency = <19200000>;
	};

	cpu_pmu: cpu-pmu {
		compatible = "arm,armv8-pmuv3";
		interrupts = <GIC_PPI 7 IRQ_TYPE_LEVEL_HIGH>;
	};

	apps_smmu_0: apps-smmu@15a00000 {
		/*
		 * reg, #global-interrupts & interrupts  properties will
		 * be added dynamically by bootloader.
		 */
		compatible = "qcom,qsmmu-v500", "qcom,virt-smmu";
		#iommu-cells = <2>;
		qcom,use-3-lvl-tables;
		dma-coherent;
	};

	apps_smmu_1: apps-smmu@15c00000 {
		/*
		 * reg, #global-interrupts & interrupts  properties will
		 * be added dynamically by bootloader.
		 */
		compatible = "qcom,qsmmu-v500", "qcom,virt-smmu";
		#iommu-cells = <2>;
		qcom,use-3-lvl-tables;
		dma-coherent;
	};

	apps_smmu_2: apps-smmu@15e00000 {
		/*
		 * reg, #global-interrupts & interrupts  properties will
		 * be added dynamically by bootloader.
		 */
		compatible = "qcom,qsmmu-v500", "qcom,virt-smmu";
		#iommu-cells = <2>;
		qcom,use-3-lvl-tables;
		dma-coherent;
	};

	kgsl_smmu_0: kgsl-smmu@3da0000 {
		/*
		 * reg, #global-interrupts & interrupts  properties will
		 * be added dynamically by bootloader.
		 */
		compatible = "qcom,qsmmu-v500", "qcom,virt-smmu";
		#iommu-cells = <2>;
		qcom,use-3-lvl-tables;
		dma-coherent;
	};

	qcom_dma_heaps: qcom,dma-heaps {
		compatible = "qcom,dma-heaps";
		qcom,hgy-secure-heap;

		qcom,qseecom {
			qcom,dma-heap-name = "qcom,qseecom";
			qcom,dma-heap-type = <HEAP_TYPE_CMA>;
			memory-region = <&qseecom_mem>;
		};

		qcom,qseecom_ta {
			qcom,dma-heap-name = "qcom,qseecom-ta";
			qcom,dma-heap-type = <HEAP_TYPE_CMA>;
			memory-region = <&qseecom_ta_mem>;
		};

		qcom-cp-pixel {
			qcom,dma-heap-name = "qcom,secure-pixel";
			qcom,dma-heap-type = <HEAP_TYPE_SECURE_CARVEOUT>;
			qcom,token = <0x80000>;
			memory-region = <&cp_pixel_mem>;
		};

		qcom-cp-nonpixel {
			qcom,dma-heap-name = "qcom,secure-non-pixel";
			qcom,dma-heap-type = <HEAP_TYPE_SECURE_CARVEOUT>;
			qcom,token = <0x100000>;
			memory-region = <&cp_nonpixel_mem>;
		};

		qcom-cp-bitstream {
			qcom,dma-heap-name = "system-secure";
			qcom,dma-heap-type = <HEAP_TYPE_SECURE_CARVEOUT>;
			qcom,token = <0x40000>;
			memory-region = <&system_secure_mem>;
		};
	};


	qcom,mem-buf {
		compatible = "qcom,mem-buf";
		qcom,mem-buf-capabilities = "consumer";
		qcom,vmid = <52>;
	};

	dma_dev@0x0 {
		compatible = "qcom,iommu-dma";
		memory-region = <&system_cma>;
	};

	hab: qcom,hab {
		compatible = "qcom,hab";
		vmid = <2>;

		mmidgrp100: mmidgrp100 {
			grp-start-id = <100>;
			role = "fe";
			remote-vmids = <0>;
			dma-coherent;
		};

		mmidgrp200: mmidgrp200 {
			grp-start-id = <200>;
			role = "fe";
			remote-vmids = <0>;
			dma-coherent;
		};

		mmidgrp300: mmidgrp300 {
			grp-start-id = <300>;
			role = "fe";
			remote-vmids = <0>;
			dma-coherent;
		};

		mmidgrp400: mmidgrp400 {
			grp-start-id = <400>;
			role = "fe";
			remote-vmids = <0>;
			dma-coherent;
		};

		mmidgrp500: mmidgrp500 {
			grp-start-id = <500>;
			role = "fe";
			remote-vmids = <0>;
			dma-coherent;
		};

		mmidgrp600: mmidgrp600 {
			grp-start-id = <600>;
			role = "fe";
			remote-vmids = <0>;
		};

		mmidgrp1400: mmidgrp1400 {
			grp-start-id = <1400>;
			role = "fe";
			remote-vmids = <0>;
		};

		mmidgrp1500: mmidgrp1500 {
			grp-start-id = <1500>;
			role = "fe";
			remote-vmids = <0>;
		};

		mmidgrp1600: mmidgrp1600 {
			grp-start-id = <1600>;
			role = "fe";
			remote-vmids = <0>;
		};

		mmidgrp1700: mmidgrp1700 {
			grp-start-id = <1700>;
			role = "fe";
			remote-vmids = <0>;
			dma-coherent;
		};

		mmidgrp1800: mmidgrp1800 {
			grp-start-id = <1800>;
			role = "fe";
			remote-vmids = <0>;
			dma-coherent;
		};

		mmidgrp1900: mmidgrp1900 {
			grp-start-id = <1900>;
			role = "fe";
			remote-vmids = <0>;
			dma-coherent;
		};
	};

	scmi {
		compatible = "arm,scmi-virtio";
		#address-cells = <1>;
		#size-cells = <0>;
		status = "ok";

		scmi_power: protocol@11 {
			reg = <0x11>;
			#power-domain-cells = <1>;
		};

		scmi_perf: protocol@13 {
			reg = <0x13>;
			#power-domain-cells = <1>;
		};

		scmi_reset: protocol@16 {
			reg = <0x16>;
			#reset-cells = <1>;
		};
	};

	qcom_rng_ee13: qrng@10cd000 {
		compatible = "qcom,msm-rng";
		reg = <0x10cd000 0x1000>;
		qcom,no-qrng-config;
		qcom,no-clock-support;
		status = "ok";
	};

	pdc: interrupt-controller@b220000 {
		compatible = "qcom,pdc";
		reg = <0xb220000 0x10000>;
		qcom,pdc-ranges = <7 752 2>, <12 757 2>, <41 786 1>;
		#interrupt-cells = <2>;
		interrupt-parent = <&intc>;
		interrupt-controller;
	};

	qcom,test-dbl-gvm1 {
		compatible = "qcom,gh-dbl";
		qcom,label = <0x4>;
	};

	qcom,test-msgq-gvm1 {
		compatible = "qcom,gh-msgq-test";
		gunyah-label = <4>;
		affinity = <0>;
	};

	qcom,gh-qtimer@17C25000 {
		compatible = "qcom,gh-qtmr";
		reg = <0x17425000 0x1000>;
		reg-names = "qtmr-base";
		interrupts = <GIC_SPI 10 IRQ_TYPE_LEVEL_HIGH>;
		interrupt-names = "qcom,qtmr-intr";
		qcom,secondary;
	};

	google,debug-kinfo {
		compatible = "google,debug-kinfo";
		memory-region = <&kinfo_mem>;
	};

	logbuf: qcom,logbuf-vendor-hooks {
		compatible = "qcom,logbuf-vendor-hooks";
	};
};

&remoteproc_cdsp_glink {
	qcom,fastrpc {
		label = "nsp";
		instance-id = <0>;
		dsp-type = <1>;
	};
};

&remoteproc_cdsp1_glink {
	qcom,fastrpc {
		label = "nsp";
		instance-id = <1>;
		dsp-type = <1>;
	};
};

&remoteproc_hpass0_glink {
	qcom,fastrpc {
		label = "hpass";
		instance-id = <0>;
		dsp-type = <5>;
	};
};

&remoteproc_hpass1_glink {
	qcom,fastrpc {
		label = "hpass";
		instance-id = <1>;
		dsp-type = <5>;
	};
};

/ {
	rename_devices: rename_devices {
		compatible = "qcom,rename-devices";
		rename_blk: rename_blk {
			device-type = "block";
			actual-dev =    "vda", "vdb", "vdc",
					"vdd", "vde", "vdf",
					"vdg", "vdh", "vdi",
					"vdj", "vdk", "vdl",
					"vdm", "vdn", "vdo",
					"vdp", "vdq", "vdr",
					"vds", "vdt", "vdu",
					"vdv", "vdw", "vdx";
			rename-dev = "super", "userdata", "metadata",
					"persist", "misc", "vbmeta_b",
					"vbmeta_a", "modem_b", "modem_a",
					"bluetooth_b", "bluetooth_a",
					"boot_b", "boot_a", "dtbo_b",
					"dtbo_a", "dsp_b", "dsp_a",
					"vendor_boot_b", "vendor_boot_a",
					"init_boot_b", "init_boot_a", "devinfo",
					"bootloader_b", "bootloader_a";
		};
	};
};
